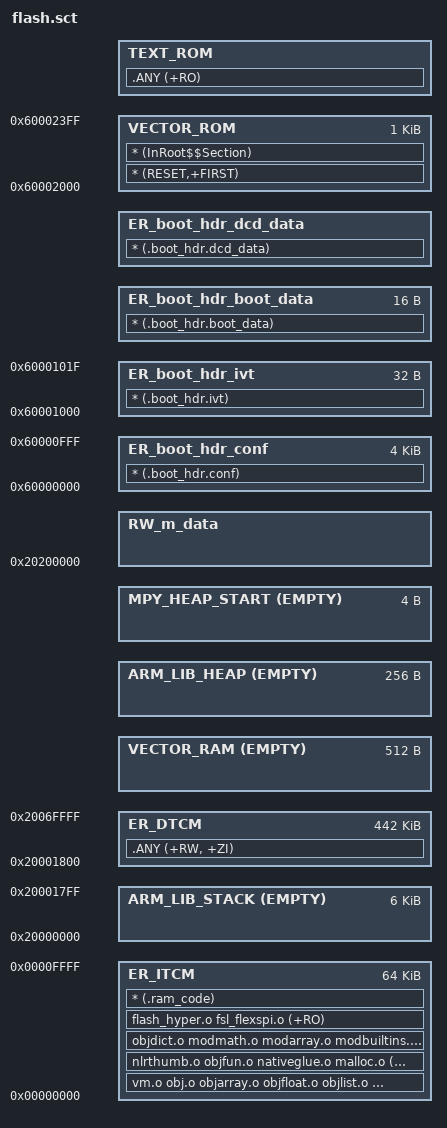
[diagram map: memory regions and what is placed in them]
#! armcc -E

#define STACK_SIZE 0x1800
#define XIP_BASE	0x60002000
#define IVT_BASE	0x60000000
#define ITCM_SIZE	64*1024
#define DTCM_SIZE	(512-64)*1024
#define OCRAM_SIZE	0

; must use "VECTOR_RAM", "RW_m_data", "VECTOR_ROM" as names to work with "InstallIRQHandler()" API

LR_XIP_FLASH_INFO IVT_BASE  {
  ; >>> RO regions
	ER_boot_hdr_conf +0 0x1000 {
	* (.boot_hdr.conf)
	}
	ER_boot_hdr_ivt IVT_BASE + 0x1000 0x20 {
	* (.boot_hdr.ivt)
	}
	ER_boot_hdr_boot_data +0 0x10{
	* (.boot_hdr.boot_data)
	}  
	ER_boot_hdr_dcd_data +0 {
	* (.boot_hdr.dcd_data)
	}
}

LR_XIP_FLASH XIP_BASE {
	VECTOR_ROM +0 0x400 { ; vector table
		* (RESET,+FIRST)
		* (InRoot$$Section)
	}
	
	TEXT_ROM +0  { ; load address = execution address
		.ANY (+RO)
	}

	ER_ITCM 0x00000000 ITCM_SIZE { ; Stack region growing down
		vm.o obj.o objarray.o objfloat.o objlist.o objobject.o  (+RO)
		nlrthumb.o objfun.o  nativeglue.o malloc.o (+RO)	
		objdict.o  modmath.o modarray.o modbuiltins.o modmicropython.o map.o (+RO)
		
		flash_hyper.o fsl_flexspi.o (+RO)
		
		* (.ram_code)
	}
	
	ARM_LIB_STACK 0x20000000 EMPTY STACK_SIZE {}
	ER_DTCM 0x20000000 + STACK_SIZE DTCM_SIZE-STACK_SIZE {
		.ANY (+RW, +ZI)
	}
	VECTOR_RAM +0 EMPTY 0x200 { ; RAM vector region (in RAMX)
	} 
	ARM_LIB_HEAP +0 EMPTY 0x100 ; Heap region growing up
	{}
	
	MPY_HEAP_START +0 EMPTY 4 {
	}	

	RW_m_data 0x20200000 OCRAM_SIZE { ; RW data
	}

	; <<<

	; >>> SDRAM >>>
	;RW_FB 0xA0000000 EMPTY UNINIT 1024*1024  {
	;}

	;RW_SDRAM 0xA0100000 EMPTY UNINIT (32-1)*1024*1024  {
	;}
	; <<<
}
